AUTOSAR XML (schema 4-3-0)
# SPDX-License-Identifier: MIT
standard types defined: SInt16, Float32
package /Cluster
  can cluster Body: baudrate=500000
    can physical channel Ch
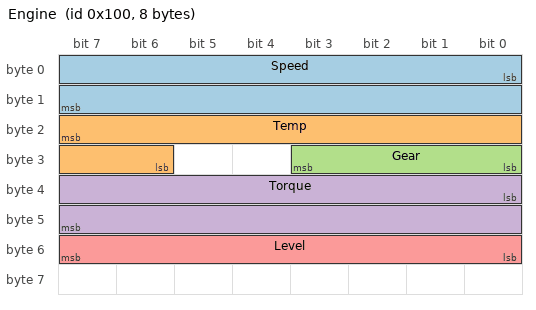
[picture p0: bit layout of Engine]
      frame Engine: id 0x100, from EMS, to Dash, frame-length=8, can-addressing-mode=STANDARD
        pdu EnginePdu: length=8
          signal Speed: start 0, 16 bit, little-endian, system signal SpeedS, init-value=0, compu {phys=raw*0.01}, unit=km/h  # Vehicle speed
          signal Temp: start 23, 10 bit, big-endian, system signal TempS, base-type=SInt16, compu {phys=raw*0.5-40}, unit=degC
          signal Gear: start 24, 4 bit, little-endian, system signal GearS, init-value=2, compu {0=Park, 1=Reverse, 2=Neutral, 3=Drive}
          signal Torque: start 32, 16 bit, little-endian, system signal TorqueS, base-type=SInt16, compu {phys=raw*0.25; unit Nm}, unit=Nm
          signal Level: start 55, 8 bit, big-endian, system signal LevelS, compu {phys=raw*0.4 for raw 0..250, 254=Error, 255=NotAvailable}, unit=%
      frame Climate: id 0x18FF1200, frame-length=8, can-addressing-mode=EXTENDED
        carries pdu ClimatePdu: packing-byte-order=little-endian, start-position=8
        pdu ClimatePdu: length=7
          signal Fan: start 0, 4 bit, little-endian, system signal FanS
          signal Ratio: start 8, 32 bit, little-endian, system signal RatioS, base-type=Float32
      frame FdFrame: id 0x300, frame-length=64, can-addressing-mode=STANDARD, can-frame-rx-behavior=CAN-FD, can-frame-tx-behavior=CAN-FD
        pdu FdPdu: length=64
          signal Head: start 0, 8 bit, little-endian, system signal HeadS
          signal Tail: start 504, 8 bit, little-endian, system signal TailS
          signal Mid: start 263, 16 bit, big-endian, system signal MidS, compu {phys=raw*0.1-1000}
package /Ecus
  ecu instance EMS
    can communication connector Conn
  ecu instance Dash
    can communication connector Conn
package /Units
  4 x unit:
    Kph: display-name=km/h
    DegC: display-name=degC
    Nm: display-name=Nm
    Pct: display-name=%
package /Mux
  multiplexed i pdu MuxPdu: length=8
